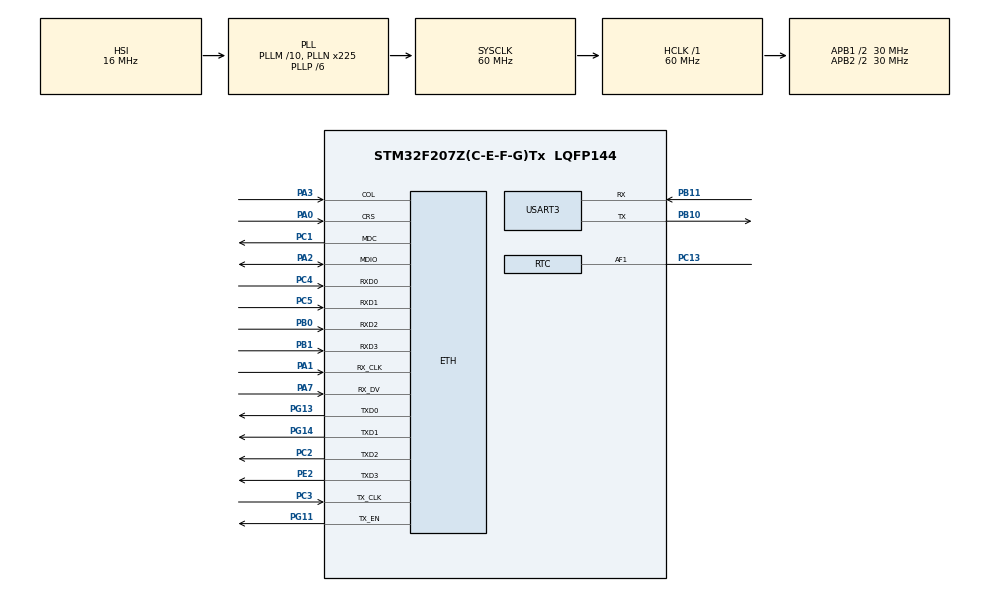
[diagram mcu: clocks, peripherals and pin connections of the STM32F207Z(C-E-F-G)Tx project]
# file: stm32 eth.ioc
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ETH.MediaInterface=ETH_MEDIA_INTERFACE_MII
ETH.PhyAddress=0
FREERTOS.Tasks01=defaultTask,0,128,StartDefaultTask,Default
LWIP.GATEWAY_ADDRESS=192.168.001.001
LWIP.IP_ADDRESS=192.168.001.225
LWIP.LWIP_DHCP=0
LWIP.LWIP_NETIF_LINK_CALLBACK=1
LWIP.LWIP_NETIF_LOOPBACK=0
LWIP.LWIP_NETIF_STATUS_CALLBACK=1
LWIP.NETMASK_ADDRESS=255.255.255.000
LWIP.SYS_LIGHTWEIGHT_PROT=0
LWIP.Version=v1.4.1_Cube
Mcu.Family=STM32F2
Mcu.Name=STM32F207Z(C-E-F-G)Tx
Mcu.Package=LQFP144
NVIC.ETH_IRQn=true\:5\:0\:false\:false\:true\:true\:true\:true
NVIC.PriorityGroup=NVIC_PRIORITYGROUP_4
NVIC.USART3_IRQn=true\:5\:0\:false\:false\:true\:true\:true\:true
PA0-WKUP.Mode=MII
PA0-WKUP.Signal=ETH_CRS
PA1.Mode=MII
PA1.Signal=ETH_RX_CLK
PA13.Mode=Serial-Wire
PA13.Signal=SYS_JTMS-SWDIO
PA14.Mode=Serial-Wire
PA14.Signal=SYS_JTCK-SWCLK
PA2.Mode=MII
PA2.Signal=ETH_MDIO
PA3.Mode=MII
PA3.Signal=ETH_COL
PA7.Mode=MII
PA7.Signal=ETH_RX_DV
PB0.Mode=MII
PB0.Signal=ETH_RXD2
PB1.Mode=MII
PB1.Signal=ETH_RXD3
PB10.Mode=Asynchronous
PB10.Signal=USART3_TX
PB11.Mode=Asynchronous
PB11.Signal=USART3_RX
PC1.Mode=MII
PC1.Signal=ETH_MDC
PC13.Mode=Timestamp enabled - Input Enabled to AF1
PC13.Signal=RTC_AF1
PC2.Mode=MII
PC2.Signal=ETH_TXD2
PC3.Mode=MII
PC3.Signal=ETH_TX_CLK
PC4.Mode=MII
PC4.Signal=ETH_RXD0
PC5.Mode=MII
PC5.Signal=ETH_RXD1
PE2.Mode=MII
PE2.Signal=ETH_TXD3
PG11.Mode=MII
PG11.Signal=ETH_TX_EN
PG13.Mode=MII
PG13.Signal=ETH_TXD0
PG14.Mode=MII
PG14.Signal=ETH_TXD1
PH0-OSC_IN.Mode=HSE-External-Oscillator
PH0-OSC_IN.Signal=RCC_OSC_IN
PH1-OSC_OUT.Mode=HSE-External-Oscillator
PH1-OSC_OUT.Signal=RCC_OSC_OUT
ProjectManager.HeapSize=0x200
ProjectManager.StackSize=0x400
ProjectManager.TargetToolchain=EWARM V7
RCC.48MHZClocksFreq_Value=90000000
RCC.AHBFreq_Value=60000000
RCC.APB1CLKDivider=RCC_HCLK_DIV2
RCC.APB1Freq_Value=30000000
RCC.APB1TimFreq_Value=60000000
RCC.APB2CLKDivider=RCC_HCLK_DIV2
RCC.APB2Freq_Value=30000000
RCC.APB2TimCLKDivider=1
RCC.APB2TimFreq_Value=30000000
RCC.CortexFreq_Value=60000000
RCC.HCLKFreq_Value=60000000
RCC.HSE_VALUE=25000000
RCC.HSI_VALUE=16000000
RCC.LSE_VALUE=32768
RCC.PLLM=10
RCC.PLLN=225
RCC.PLLP=RCC_PLLP_DIV6
RCC.SYSCLKFreq_VALUE=60000000
RCC.SYSCLKSource=RCC_SYSCLKSOURCE_PLLCLK
RCC.VCOOutputFreq_Value=360000000
RTC.TimeStampPin-Timestamp\ enabled\ =RTC_TIMESTAMPPIN_DEFAULT
RTC.TimeStampPin-Timestamp\ enabled\ -\ Input\ Enabled\ to\ AF1=RTC_TIMESTAMPPIN_DEFAULT
USART3.VirtualMode=VM_ASYNC
VP_FREERTOS_VS_ENABLE.Mode=Enabled
VP_LWIP_VS_Enabled.Mode=Enabled
board=EVSE_small_2

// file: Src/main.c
/**
  ******************************************************************************
  * File Name          : main.c
  * Description        : Main program body
  ******************************************************************************
  *
  * COPYRIGHT(c) 2020 STMicroelectronics
  *
  * Redistribution and use in source and binary forms, with or without modification,
  * are permitted provided that the following conditions are met:
  *   1. Redistributions of source code must retain the above copyright notice,
  *      this list of conditions and the following disclaimer.
  *   2. Redistributions in binary form must reproduce the above copyright notice,
  *      this list of conditions and the following disclaimer in the documentation
  *      and/or other materials provided with the distribution.
  *   3. Neither the name of STMicroelectronics nor the names of its contributors
  *      may be used to endorse or promote products derived from this software
  *      without specific prior written permission.
  *
  * THIS SOFTWARE IS PROVIDED BY THE COPYRIGHT HOLDERS AND CONTRIBUTORS "AS IS"
  * AND ANY EXPRESS OR IMPLIED WARRANTIES, INCLUDING, BUT NOT LIMITED TO, THE
  * IMPLIED WARRANTIES OF MERCHANTABILITY AND FITNESS FOR A PARTICULAR PURPOSE ARE
  * DISCLAIMED. IN NO EVENT SHALL THE COPYRIGHT HOLDER OR CONTRIBUTORS BE LIABLE
  * FOR ANY DIRECT, INDIRECT, INCIDENTAL, SPECIAL, EXEMPLARY, OR CONSEQUENTIAL
  * DAMAGES (INCLUDING, BUT NOT LIMITED TO, PROCUREMENT OF SUBSTITUTE GOODS OR
  * SERVICES; LOSS OF USE, DATA, OR PROFITS; OR BUSINESS INTERRUPTION) HOWEVER
  * CAUSED AND ON ANY THEORY OF LIABILITY, WHETHER IN CONTRACT, STRICT LIABILITY,
  * OR TORT (INCLUDING NEGLIGENCE OR OTHERWISE) ARISING IN ANY WAY OUT OF THE USE
  * OF THIS SOFTWARE, EVEN IF ADVISED OF THE POSSIBILITY OF SUCH DAMAGE.
  *
  ******************************************************************************
  */
#include "stm32f2xx_hal.h"
#include "cmsis_os.h"

/* USER CODE BEGIN Includes */
#include<string.h>
#include "ocpp_cb.h"
/* USER CODE END Includes */

RTC_HandleTypeDef hrtc;

UART_HandleTypeDef huart3;

osThreadId defaultTaskHandle;

/* USER CODE BEGIN PV */
/* Private variables ---------------------------------------------------------*/
int ch=1;
/* USER CODE END PV */

void SystemClock_Config(void);
static void MX_GPIO_Init(void);
static void SystemClock_Config(void);
static void MX_RTC_Init(void);
static void MX_USART3_UART_Init(void);
void StartDefaultTask(void const * argument);

/* USER CODE BEGIN PFP */
/* Private function prototypes -----------------------------------------------*/

/* USER CODE END PFP */

/* USER CODE BEGIN 0 */
int i=0;
/* USER CODE END 0 */

int main(void)
{

  /* MCU Configuration----------------------------------------------------------*/

  /* Reset of all peripherals, Initializes the Flash interface and the Systick. */
  HAL_Init();

  /* Configure the system clock */
  SystemClock_Config();

  /* Initialize all configured peripherals */
  MX_GPIO_Init();
  SystemClock_Config();
  MX_RTC_Init();
  MX_USART3_UART_Init();

  /* Create the thread(s) */
  /* definition and creation of defaultTask */
  osThreadDef(defaultTask, StartDefaultTask, osPriorityNormal, 0, 1024);
  defaultTaskHandle = osThreadCreate(osThread(defaultTask), NULL);

  /* Start scheduler */
  osKernelStart();

  /* We should never get here as control is now taken by the scheduler */

  /* Infinite loop */
  while (1)
  {

  }

}

/** System Clock Configuration
*/
void SystemClock_Config(void)
{

  RCC_OscInitTypeDef RCC_OscInitStruct;
  RCC_ClkInitTypeDef RCC_ClkInitStruct;
  RCC_PeriphCLKInitTypeDef PeriphClkInitStruct;

  RCC_OscInitStruct.OscillatorType = RCC_OSCILLATORTYPE_HSI|RCC_OSCILLATORTYPE_LSI;
  RCC_OscInitStruct.HSIState = RCC_HSI_ON;
  RCC_OscInitStruct.HSICalibrationValue = 16;
  RCC_OscInitStruct.LSIState = RCC_LSI_ON;
  RCC_OscInitStruct.PLL.PLLState = RCC_PLL_ON;
  RCC_OscInitStruct.PLL.PLLSource = RCC_PLLSOURCE_HSI;
  RCC_OscInitStruct.PLL.PLLM = 10;
  RCC_OscInitStruct.PLL.PLLN = 225;
  RCC_OscInitStruct.PLL.PLLP = RCC_PLLP_DIV6;
  RCC_OscInitStruct.PLL.PLLQ = 4;
  HAL_RCC_OscConfig(&RCC_OscInitStruct);

  RCC_ClkInitStruct.ClockType = RCC_CLOCKTYPE_HCLK|RCC_CLOCKTYPE_SYSCLK
                              |RCC_CLOCKTYPE_PCLK1|RCC_CLOCKTYPE_PCLK2;
  RCC_ClkInitStruct.SYSCLKSource = RCC_SYSCLKSOURCE_PLLCLK;
  RCC_ClkInitStruct.AHBCLKDivider = RCC_SYSCLK_DIV1;
  RCC_ClkInitStruct.APB1CLKDivider = RCC_HCLK_DIV2;
  RCC_ClkInitStruct.APB2CLKDivider = RCC_HCLK_DIV2;
  HAL_RCC_ClockConfig(&RCC_ClkInitStruct, FLASH_LATENCY_1);

  PeriphClkInitStruct.PeriphClockSelection = RCC_PERIPHCLK_RTC;
  PeriphClkInitStruct.RTCClockSelection = RCC_RTCCLKSOURCE_LSI;
  HAL_RCCEx_PeriphCLKConfig(&PeriphClkInitStruct);

  HAL_SYSTICK_Config(HAL_RCC_GetHCLKFreq()/1000);

  HAL_SYSTICK_CLKSourceConfig(SYSTICK_CLKSOURCE_HCLK);

  /* SysTick_IRQn interrupt configuration */
  HAL_NVIC_SetPriority(SysTick_IRQn, 15, 0);
}

/* RTC init function */
void MX_RTC_Init(void)
{

  RTC_TimeTypeDef sTime;
  RTC_DateTypeDef sDate;

    /**Initialize RTC and set the Time and Date
    */
  hrtc.Instance = RTC;
  hrtc.Init.HourFormat = RTC_HOURFORMAT_24;
  hrtc.Init.AsynchPrediv = 127;
  hrtc.Init.SynchPrediv = 255;
  hrtc.Init.OutPut = RTC_OUTPUT_DISABLE;
  hrtc.Init.OutPutPolarity = RTC_OUTPUT_POLARITY_HIGH;
  hrtc.Init.OutPutType = RTC_OUTPUT_TYPE_OPENDRAIN;
  HAL_RTC_Init(&hrtc);

  sTime.Hours = 0x0;
  sTime.Minutes = 0x0;
  sTime.Seconds = 0x0;
  sTime.DayLightSaving = RTC_DAYLIGHTSAVING_NONE;
  sTime.StoreOperation = RTC_STOREOPERATION_RESET;
  HAL_RTC_SetTime(&hrtc, &sTime, RTC_FORMAT_BCD);

  sDate.WeekDay = RTC_WEEKDAY_MONDAY;
  sDate.Month = RTC_MONTH_JANUARY;
  sDate.Date = 0x1;
  sDate.Year = 0x0;

  HAL_RTC_SetDate(&hrtc, &sDate, RTC_FORMAT_BCD);

    /**Enable the TimeStamp
    */
  HAL_RTCEx_SetTimeStamp(&hrtc, RTC_TIMESTAMPEDGE_RISING, RTC_TIMESTAMPPIN_DEFAULT);

}

/* USART3 init function */
void MX_USART3_UART_Init(void)
{

  huart3.Instance = USART3;
  huart3.Init.BaudRate = 115200;
  huart3.Init.WordLength = UART_WORDLENGTH_8B;
  huart3.Init.StopBits = UART_STOPBITS_1;
  huart3.Init.Parity = UART_PARITY_NONE;
  huart3.Init.Mode = UART_MODE_TX_RX;
  huart3.Init.HwFlowCtl = UART_HWCONTROL_NONE;
  huart3.Init.OverSampling = UART_OVERSAMPLING_16;
  HAL_UART_Init(&huart3);

}

/** Configure pins as
        * Analog
        * Input
        * Output
        * EVENT_OUT
        * EXTI
*/
void MX_GPIO_Init(void)
{

  /* GPIO Ports Clock Enable */
  __HAL_RCC_GPIOE_CLK_ENABLE();
  __HAL_RCC_GPIOC_CLK_ENABLE();
  __HAL_RCC_GPIOH_CLK_ENABLE();
  __HAL_RCC_GPIOA_CLK_ENABLE();
  __HAL_RCC_GPIOB_CLK_ENABLE();
  __HAL_RCC_GPIOG_CLK_ENABLE();

}

/* StartDefaultTask function */
void StartDefaultTask(void const * argument)
{
  /* init code for LWIP */

  char str[]="h,AA00\r\n";
  MX_LWIP_Init();

  /* USER CODE BEGIN 5 */
  osDelay(2000);

  client_connect();
  /* Infinite loop */
  for(;;)
  {
    ch=netconn_write(xNetConn,str,strlen(str),NETCONN_NOFLAG);
    osDelay(2000);

  }
  /* USER CODE END 5 */
}

/************************ (C) COPYRIGHT STMicroelectronics *****END OF FILE****/
